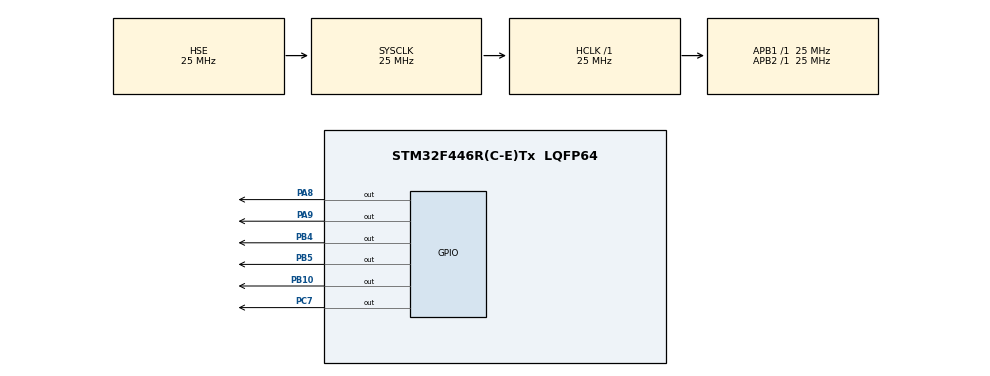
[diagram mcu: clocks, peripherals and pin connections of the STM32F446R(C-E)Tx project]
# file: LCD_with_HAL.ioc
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Mcu.Family=STM32F4
Mcu.Name=STM32F446R(C-E)Tx
Mcu.Package=LQFP64
NVIC.PriorityGroup=NVIC_PRIORITYGROUP_4
PA13.Mode=Serial_Wire
PA13.Signal=SYS_JTMS-SWDIO
PA14.Mode=Serial_Wire
PA14.Signal=SYS_JTCK-SWCLK
PA8.Signal=GPIO_Output
PA9.Signal=GPIO_Output
PB10.Signal=GPIO_Output
PB4.Signal=GPIO_Output
PB5.Signal=GPIO_Output
PC7.Signal=GPIO_Output
PH0-OSC_IN.Mode=HSE-External-Oscillator
PH0-OSC_IN.Signal=RCC_OSC_IN
PH1-OSC_OUT.Mode=HSE-External-Oscillator
PH1-OSC_OUT.Signal=RCC_OSC_OUT
ProjectManager.HeapSize=0x200
ProjectManager.StackSize=0x400
ProjectManager.TargetToolchain=STM32CubeIDE
RCC.AHBFreq_Value=25000000
RCC.APB1Freq_Value=25000000
RCC.APB1TimFreq_Value=25000000
RCC.APB2Freq_Value=25000000
RCC.APB2TimFreq_Value=25000000
RCC.CortexFreq_Value=25000000
RCC.HCLKFreq_Value=25000000
RCC.PLLSourceVirtual=RCC_PLLSOURCE_HSE
RCC.SYSCLKFreq_VALUE=25000000
RCC.SYSCLKSource=RCC_SYSCLKSOURCE_HSE
RCC.USBFreq_Value=150000000
RCC.VCOOutputFreq_Value=300000000
board=custom

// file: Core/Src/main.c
/* USER CODE BEGIN Header */
/**
  ******************************************************************************
  * @file           : main.c
  * @brief          : Main program body
  ******************************************************************************
  * @attention
  *
  * Copyright (c) 2024 STMicroelectronics.
  * All rights reserved.
  *
  * This software is licensed under terms that can be found in the LICENSE file
  * in the root directory of this software component.
  * If no LICENSE file comes with this software, it is provided AS-IS.
  *
  ******************************************************************************
  */
/* USER CODE END Header */
#include "main.h"
#include "LCD.h"

void SystemClock_Config(void);
static void MX_GPIO_Init(void);

int main(void)
{

  /* MCU Configuration--------------------------------------------------------*/

  /* Reset of all peripherals, Initializes the Flash interface and the Systick. */
  HAL_Init();

  /* Configure the system clock */
  SystemClock_Config();

  /* Initialize all configured peripherals */
  MX_GPIO_Init();
  /* USER CODE BEGIN 2 */
  // Initialize the LCD
     LCD_Init();

     // Clear the LCD screen
     LCD_Clear();

     // Set the cursor to the first row, first column
     LCD_SetCursor(0, 0);          // Set cursor to first row, first column
         LCD_SendString("Hello World!");

         // Move to the second line
         LCD_SetCursor(1, 0);
         LCD_SendString("STM32 Rocks!");

  /* USER CODE END 2 */

  /* Infinite loop */
  while (1)
  {

  }
}

void SystemClock_Config(void)
{
  RCC_OscInitTypeDef RCC_OscInitStruct = {0};
  RCC_ClkInitTypeDef RCC_ClkInitStruct = {0};

  /** Configure the main internal regulator output voltage
  */
  __HAL_RCC_PWR_CLK_ENABLE();
  __HAL_PWR_VOLTAGESCALING_CONFIG(PWR_REGULATOR_VOLTAGE_SCALE3);

  /** Initializes the RCC Oscillators according to the specified parameters
  * in the RCC_OscInitTypeDef structure.
  */
  RCC_OscInitStruct.OscillatorType = RCC_OSCILLATORTYPE_HSE;
  RCC_OscInitStruct.HSEState = RCC_HSE_ON;
  RCC_OscInitStruct.PLL.PLLState = RCC_PLL_NONE;
  if (HAL_RCC_OscConfig(&RCC_OscInitStruct) != HAL_OK)
  {
    Error_Handler();
  }

  /** Initializes the CPU, AHB and APB buses clocks
  */
  RCC_ClkInitStruct.ClockType = RCC_CLOCKTYPE_HCLK|RCC_CLOCKTYPE_SYSCLK
                              |RCC_CLOCKTYPE_PCLK1|RCC_CLOCKTYPE_PCLK2;
  RCC_ClkInitStruct.SYSCLKSource = RCC_SYSCLKSOURCE_HSE;
  RCC_ClkInitStruct.AHBCLKDivider = RCC_SYSCLK_DIV1;
  RCC_ClkInitStruct.APB1CLKDivider = RCC_HCLK_DIV1;
  RCC_ClkInitStruct.APB2CLKDivider = RCC_HCLK_DIV1;

  if (HAL_RCC_ClockConfig(&RCC_ClkInitStruct, FLASH_LATENCY_0) != HAL_OK)
  {
    Error_Handler();
  }
}

static void MX_GPIO_Init(void)
{
  GPIO_InitTypeDef GPIO_InitStruct = {0};

  /* GPIO Ports Clock Enable */
  __HAL_RCC_GPIOH_CLK_ENABLE();
  __HAL_RCC_GPIOB_CLK_ENABLE();
  __HAL_RCC_GPIOC_CLK_ENABLE();
  __HAL_RCC_GPIOA_CLK_ENABLE();

  /*Configure GPIO pin Output Level */
  HAL_GPIO_WritePin(GPIOB, GPIO_PIN_10|GPIO_PIN_4|GPIO_PIN_5, GPIO_PIN_RESET);

  /*Configure GPIO pin Output Level */
  HAL_GPIO_WritePin(GPIOC, GPIO_PIN_7, GPIO_PIN_RESET);

  /*Configure GPIO pin Output Level */
  HAL_GPIO_WritePin(GPIOA, GPIO_PIN_8|GPIO_PIN_9, GPIO_PIN_RESET);

  /*Configure GPIO pins : PB10 PB4 PB5 */
  GPIO_InitStruct.Pin = GPIO_PIN_10|GPIO_PIN_4|GPIO_PIN_5;
  GPIO_InitStruct.Mode = GPIO_MODE_OUTPUT_PP;
  GPIO_InitStruct.Pull = GPIO_NOPULL;
  GPIO_InitStruct.Speed = GPIO_SPEED_FREQ_LOW;
  HAL_GPIO_Init(GPIOB, &GPIO_InitStruct);

  /*Configure GPIO pin : PC7 */
  GPIO_InitStruct.Pin = GPIO_PIN_7;
  GPIO_InitStruct.Mode = GPIO_MODE_OUTPUT_PP;
  GPIO_InitStruct.Pull = GPIO_NOPULL;
  GPIO_InitStruct.Speed = GPIO_SPEED_FREQ_LOW;
  HAL_GPIO_Init(GPIOC, &GPIO_InitStruct);

  /*Configure GPIO pins : PA8 PA9 */
  GPIO_InitStruct.Pin = GPIO_PIN_8|GPIO_PIN_9;
  GPIO_InitStruct.Mode = GPIO_MODE_OUTPUT_PP;
  GPIO_InitStruct.Pull = GPIO_NOPULL;
  GPIO_InitStruct.Speed = GPIO_SPEED_FREQ_LOW;
  HAL_GPIO_Init(GPIOA, &GPIO_InitStruct);

}

void Error_Handler(void)
{
  __disable_irq();
  while (1)
  {
  }
}
